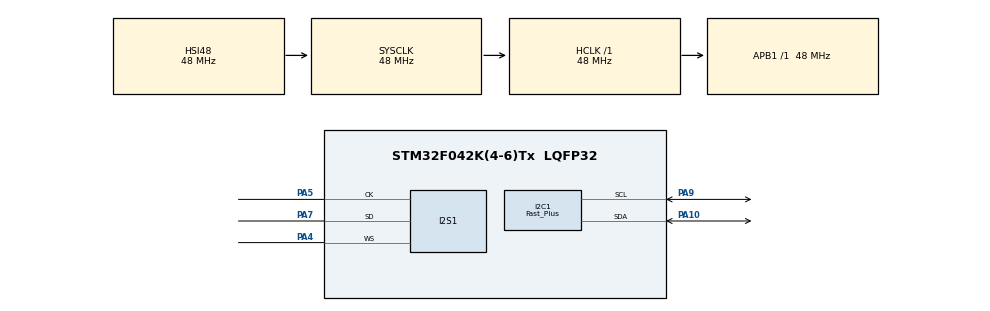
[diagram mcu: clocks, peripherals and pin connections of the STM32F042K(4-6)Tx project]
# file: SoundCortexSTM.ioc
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Dma.Request0=SPI1_TX
Dma.SPI1_TX.0.Direction=DMA_MEMORY_TO_PERIPH
Dma.SPI1_TX.0.Instance=DMA1_Channel3
Dma.SPI1_TX.0.MemDataAlignment=DMA_MDATAALIGN_HALFWORD
Dma.SPI1_TX.0.MemInc=DMA_MINC_ENABLE
Dma.SPI1_TX.0.Mode=DMA_CIRCULAR
Dma.SPI1_TX.0.PeriphDataAlignment=DMA_PDATAALIGN_HALFWORD
Dma.SPI1_TX.0.PeriphInc=DMA_PINC_DISABLE
Dma.SPI1_TX.0.Priority=DMA_PRIORITY_VERY_HIGH
I2C1.DualAddressMode=I2C_DUALADDRESS_ENABLE
I2C1.GeneralCallMode=I2C_GENERALCALL_ENABLE
I2C1.I2C_Speed_Mode=I2C_Fast_Plus
I2C1.OwnAddress=PSG_ADDRESS
I2C1.OwnAddress2=SCC_ADDRESS
I2C1.Timing=0x00000001
I2S1.AudioFreq=I2S_AUDIOFREQ_48K
I2S1.ErrorAudioFreq=0.8 %
I2S1.FullDuplexMode=I2S_FULLDUPLEXMODE_DISABLE
I2S1.Instance=SPI$Index
I2S1.RealAudioFreq=48.387 KHz
I2S1.VirtualMode=I2S_MODE_MASTER
Mcu.Family=STM32F0
Mcu.Name=STM32F042K(4-6)Tx
Mcu.Package=LQFP32
NVIC.DMA1_Channel2_3_IRQn=true\:0\:0\:false\:false\:true\:false
NVIC.I2C1_IRQn=true\:2\:0\:true\:false\:true\:true
PA10.GPIO_FMA10=SYSCFG_CFGR1_I2C_FMP_PA10
PA10.Mode=I2C
PA10.Signal=I2C1_SDA
PA4.Mode=Half_Duplex_Master
PA4.Signal=I2S1_WS
PA5.Mode=Half_Duplex_Master
PA5.Signal=I2S1_CK
PA7.Mode=Half_Duplex_Master
PA7.Signal=I2S1_SD
PA9.GPIO_FMA9=SYSCFG_CFGR1_I2C_FMP_PA9
PA9.Mode=I2C
PA9.Signal=I2C1_SCL
ProjectManager.HeapSize=0x200
ProjectManager.StackSize=0x400
ProjectManager.TargetToolchain=SW4STM32
RCC.AHBFreq_Value=48000000
RCC.APB1Freq_Value=48000000
RCC.APB1TimFreq_Value=48000000
RCC.HCLKFreq_Value=48000000
RCC.SYSCLKFreq_VALUE=48000000
RCC.SYSCLKSource=RCC_SYSCLKSOURCE_HSI48
board=custom

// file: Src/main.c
/* USER CODE BEGIN Header */
/**
  ******************************************************************************
  * @file           : main.c
  * @brief          : Main program body
  ******************************************************************************
  ** This notice applies to any and all portions of this file
  * that are not between comment pairs USER CODE BEGIN and
  * USER CODE END. Other portions of this file, whether
  * inserted by the user or by software development tools
  * are owned by their respective copyright owners.
  *
  * COPYRIGHT(c) 2019 STMicroelectronics
  *
  * Redistribution and use in source and binary forms, with or without modification,
  * are permitted provided that the following conditions are met:
  *   1. Redistributions of source code must retain the above copyright notice,
  *      this list of conditions and the following disclaimer.
  *   2. Redistributions in binary form must reproduce the above copyright notice,
  *      this list of conditions and the following disclaimer in the documentation
  *      and/or other materials provided with the distribution.
  *   3. Neither the name of STMicroelectronics nor the names of its contributors
  *      may be used to endorse or promote products derived from this software
  *      without specific prior written permission.
  *
  * THIS SOFTWARE IS PROVIDED BY THE COPYRIGHT HOLDERS AND CONTRIBUTORS "AS IS"
  * AND ANY EXPRESS OR IMPLIED WARRANTIES, INCLUDING, BUT NOT LIMITED TO, THE
  * IMPLIED WARRANTIES OF MERCHANTABILITY AND FITNESS FOR A PARTICULAR PURPOSE ARE
  * DISCLAIMED. IN NO EVENT SHALL THE COPYRIGHT HOLDER OR CONTRIBUTORS BE LIABLE
  * FOR ANY DIRECT, INDIRECT, INCIDENTAL, SPECIAL, EXEMPLARY, OR CONSEQUENTIAL
  * DAMAGES (INCLUDING, BUT NOT LIMITED TO, PROCUREMENT OF SUBSTITUTE GOODS OR
  * SERVICES; LOSS OF USE, DATA, OR PROFITS; OR BUSINESS INTERRUPTION) HOWEVER
  * CAUSED AND ON ANY THEORY OF LIABILITY, WHETHER IN CONTRACT, STRICT LIABILITY,
  * OR TORT (INCLUDING NEGLIGENCE OR OTHERWISE) ARISING IN ANY WAY OUT OF THE USE
  * OF THIS SOFTWARE, EVEN IF ADVISED OF THE POSSIBILITY OF SUCH DAMAGE.
  *
  ******************************************************************************
  */
/* USER CODE END Header */

#include "main.h"

/* USER CODE BEGIN Includes */
#include "BuildConfig.h"
#include "SoundCortex.h"
/* USER CODE END Includes */

I2C_HandleTypeDef hi2c1;

I2S_HandleTypeDef hi2s1;
DMA_HandleTypeDef hdma_spi1_tx;

void SystemClock_Config(void);
static void MX_GPIO_Init(void);
static void MX_DMA_Init(void);
static void MX_I2C1_Init(void);
static void MX_I2S1_Init(void);
/* USER CODE BEGIN PFP */
extern void initialise_monitor_handles();
/* USER CODE END PFP */

/* USER CODE BEGIN 0 */
int16_t buffer[4];
void HAL_I2S_TxHalfCpltCallback(I2S_HandleTypeDef *hi2s) {
  buffer[0] = SoundCortexUpdate() << 5;
  buffer[1] = buffer[0];
}
void HAL_I2S_TxCpltCallback(I2S_HandleTypeDef *hi2s) {
  buffer[2] = SoundCortexUpdate() << 5;
  buffer[3] = buffer[2];
}

/* USER CODE END 0 */

int main(void)
{
  /* USER CODE BEGIN 1 */
  initialise_monitor_handles();

  /* USER CODE END 1 */

  /* MCU Configuration--------------------------------------------------------*/

  /* Reset of all peripherals, Initializes the Flash interface and the Systick. */
  HAL_Init();

  /* Configure the system clock */
  SystemClock_Config();

  /* Initialize all configured peripherals */
  MX_GPIO_Init();
  MX_DMA_Init();
  MX_I2C1_Init();
  MX_I2S1_Init();
  /* USER CODE BEGIN 2 */
  SoundCortexInit(48387);
  HAL_I2S_Transmit_DMA(&hi2s1, buffer, 4);
  /* USER CODE END 2 */

  /* Infinite loop */
  while (1)
  {

  }
}

void SystemClock_Config(void)
{
  RCC_OscInitTypeDef RCC_OscInitStruct = {0};
  RCC_ClkInitTypeDef RCC_ClkInitStruct = {0};
  RCC_PeriphCLKInitTypeDef PeriphClkInit = {0};

  /**Initializes the CPU, AHB and APB busses clocks
  */
  RCC_OscInitStruct.OscillatorType = RCC_OSCILLATORTYPE_HSI|RCC_OSCILLATORTYPE_HSI48;
  RCC_OscInitStruct.HSIState = RCC_HSI_ON;
  RCC_OscInitStruct.HSI48State = RCC_HSI48_ON;
  RCC_OscInitStruct.HSICalibrationValue = RCC_HSICALIBRATION_DEFAULT;
  RCC_OscInitStruct.PLL.PLLState = RCC_PLL_NONE;
  if (HAL_RCC_OscConfig(&RCC_OscInitStruct) != HAL_OK)
  {
    Error_Handler();
  }
  /**Initializes the CPU, AHB and APB busses clocks
  */
  RCC_ClkInitStruct.ClockType = RCC_CLOCKTYPE_HCLK|RCC_CLOCKTYPE_SYSCLK
                              |RCC_CLOCKTYPE_PCLK1;
  RCC_ClkInitStruct.SYSCLKSource = RCC_SYSCLKSOURCE_HSI48;
  RCC_ClkInitStruct.AHBCLKDivider = RCC_SYSCLK_DIV1;
  RCC_ClkInitStruct.APB1CLKDivider = RCC_HCLK_DIV1;

  if (HAL_RCC_ClockConfig(&RCC_ClkInitStruct, FLASH_LATENCY_1) != HAL_OK)
  {
    Error_Handler();
  }
  PeriphClkInit.PeriphClockSelection = RCC_PERIPHCLK_I2C1;
  PeriphClkInit.I2c1ClockSelection = RCC_I2C1CLKSOURCE_HSI;
  if (HAL_RCCEx_PeriphCLKConfig(&PeriphClkInit) != HAL_OK)
  {
    Error_Handler();
  }
}

static void MX_I2C1_Init(void)
{

  hi2c1.Instance = I2C1;
  hi2c1.Init.Timing = 0x00000001;
  hi2c1.Init.OwnAddress1 = (PSG_ADDRESS*2);
  hi2c1.Init.AddressingMode = I2C_ADDRESSINGMODE_7BIT;
  hi2c1.Init.DualAddressMode = I2C_DUALADDRESS_ENABLE;
  hi2c1.Init.OwnAddress2 = (SCC_ADDRESS*2);
  hi2c1.Init.OwnAddress2Masks = I2C_OA2_NOMASK;
  hi2c1.Init.GeneralCallMode = I2C_GENERALCALL_ENABLE;
  hi2c1.Init.NoStretchMode = I2C_NOSTRETCH_DISABLE;
  if (HAL_I2C_Init(&hi2c1) != HAL_OK)
  {
    Error_Handler();
  }
  /**Configure Analogue filter
  */
  if (HAL_I2CEx_ConfigAnalogFilter(&hi2c1, I2C_ANALOGFILTER_ENABLE) != HAL_OK)
  {
    Error_Handler();
  }
  /**Configure Digital filter
  */
  if (HAL_I2CEx_ConfigDigitalFilter(&hi2c1, 0) != HAL_OK)
  {
    Error_Handler();
  }
  /**I2C Fast mode Plus enable
  */
  __HAL_SYSCFG_FASTMODEPLUS_ENABLE(I2C_FASTMODEPLUS_I2C1);

}

static void MX_I2S1_Init(void)
{

  hi2s1.Instance = SPI1;
  hi2s1.Init.Mode = I2S_MODE_MASTER_TX;
  hi2s1.Init.Standard = I2S_STANDARD_PHILIPS;
  hi2s1.Init.DataFormat = I2S_DATAFORMAT_16B;
  hi2s1.Init.MCLKOutput = I2S_MCLKOUTPUT_DISABLE;
  hi2s1.Init.AudioFreq = I2S_AUDIOFREQ_48K;
  hi2s1.Init.CPOL = I2S_CPOL_LOW;
  if (HAL_I2S_Init(&hi2s1) != HAL_OK)
  {
    Error_Handler();
  }

}

static void MX_DMA_Init(void)
{
  /* DMA controller clock enable */
  __HAL_RCC_DMA1_CLK_ENABLE();

  /* DMA interrupt init */
  /* DMA1_Channel2_3_IRQn interrupt configuration */
  HAL_NVIC_SetPriority(DMA1_Channel2_3_IRQn, 0, 0);
  HAL_NVIC_EnableIRQ(DMA1_Channel2_3_IRQn);

}

static void MX_GPIO_Init(void)
{

  /* GPIO Ports Clock Enable */
  __HAL_RCC_GPIOA_CLK_ENABLE();

}

void Error_Handler(void)
{
}

/************************ (C) COPYRIGHT STMicroelectronics *****END OF FILE****/
